# RS1xxxx register map
Vendor: Silicon Lab Inc.; Series: ARMCM4; File version: 1.2
CPU: CM4 r1p0, little endian, MPU, FPU, 6 interrupt priority bits
Registers are 32-bit, read-write, reset 0x0 unless marked. A register's access mark holds for its fields unless they carry their own. Offsets are from the block's base; [hi:lo] are bit positions.

## BAND_GAP_TOP
Base 0x2405A400
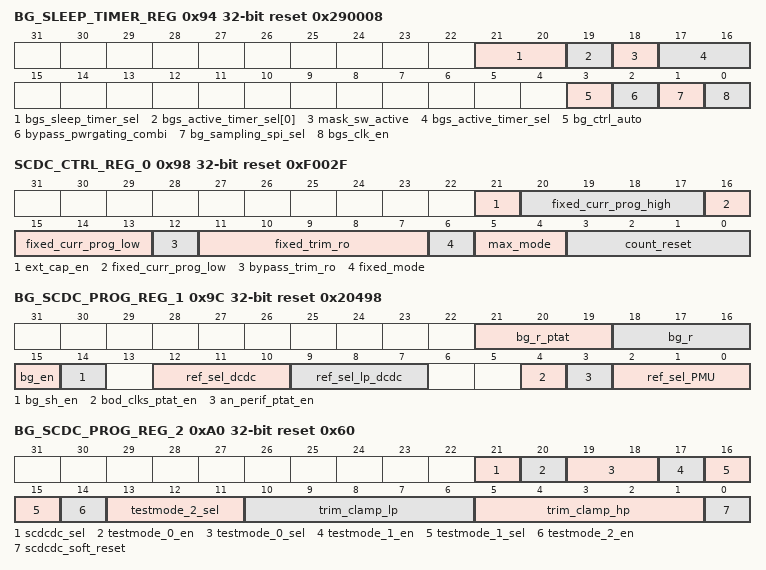
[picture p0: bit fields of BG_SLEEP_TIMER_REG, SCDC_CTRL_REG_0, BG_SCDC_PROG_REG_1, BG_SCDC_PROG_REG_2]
0x94 BG_SLEEP_TIMER_REG reset 0x290008 — BG sleep timer register
  [21:20] bgs_sleep_timer_sel — sleep timer count is 2'd0: active_timer_count * 2^6 2'd1: active timer_count * 2^7 2'd2: active_timer_count * 2^8 2'd3: active_timer_count * 2^9
  [19] bgs_active_timer_sel[0] ro — taking one bit of bgs_active_timer_sel[17:16]
  [18] mask_sw_active — 1: disable comp clock in between sleep duration
  [17:16] bgs_active_timer_sel — Active timer select
  [3] bg_ctrl_auto — bg_en , bg_sh_en automatically enables or take values though SPI
    1=Enable (bg_en and bg_sh_en are automatically controlled); 0=Disable (bg_en and sh_en take values from SPI.)
  [2] bypass_pwrgating_combi — Powergating is disabled for combi logic . It will always be ON.
  [1] bg_sampling_spi_sel — enable bandgap sampling through spi / pin
    1=Through_SPI (Bandgap sampling through spi); 0=Through_Pin (Band gap sampling through pin(sleep_en))
  [0] bgs_clk_en — bandgap sampling enable through spi
0x98 SCDC_CTRL_REG_0 reset 0xF002F — SCDC Control register
  [21] ext_cap_en — To change current trim bits to high or low through spi, based on high power or low power mode.When 0, curr prog value is 0.
  [20:17] fixed_curr_prog_high — Current prog value to take when ext cap en is high and sel_high freq_ext_b is 0
  [16:13] fixed_curr_prog_low — Current prog value to take when ext cap en is high and sel_high freq_ext_b is 1
  [12] bypass_trim_ro — To program the trim value manually, irrespective of the fsm
  [11:7] fixed_trim_ro — Manual trim word
  [6] fixed_mode
  [5:4] max_mode — maximum mode it can go to
  [3:0] count_reset — Count reset value, count threshold will be doubler this value
0x9C BG_SCDC_PROG_REG_1 reset 0x20498 — BG SCDC programme register
  [21:19] bg_r_ptat — Bandgap voltage programming
  [18:16] bg_r — Bandgap voltage programming
  [15] bg_en — bg_en from spi
  [14] bg_sh_en — bg_sh_en from spi
  [12:10] ref_sel_dcdc — DCDC output programming vref_1p1/vref_1p05
  [9:7] ref_sel_lp_dcdc — DCDC output programming in LDO high/low power mode
  [4] bod_clks_ptat_en — 1 - To enable ptat currents to clocks and bod(cmp_npss)
  [3] an_perif_ptat_en — 1 - To enable ptat currents to analog peripherals
  [2:0] ref_sel_PMU — 3'd0 - 1.2V, 3'd1 - 1.15V, 3'd2 - 1.1V, 3'd3 - 1.05V 3'd4 - 1.0V 3'd5 - 0.95V,3'd6 - 0.9V,3'd7 - 0.85V
0xA0 BG_SCDC_PROG_REG_2 reset 0x60 — BG SCDC programme register 2
  [21] scdcdc_sel — To switch to SCDCDC mode from LDO mode.1 - SCDC mode,0 - LDO mode
    1=SCDC_Mode; 0=LDO_Mode
  [20] testmode_0_en — Enable for output on to BG_TESTMODE0
  [19:18] testmode_0_sel — Test mode 0 select
  [17] testmode_1_en — To enable test mux for BG_TESTMODE1
  [16:15] testmode_1_sel — testmode 1 select
  [14] testmode_2_en — To enable testmux for BG_TESTMODE2
  [13:11] testmode_2_sel — test mode 2 select
  [10:6] trim_clamp_lp — trim value lower clamp value when sel high freq_b is 1
  [5:1] trim_clamp_hp — trim value lower clamp value when sel high freq_b is 0
  [0] scdcdc_soft_reset — soft reset signal for scdcdc fsm
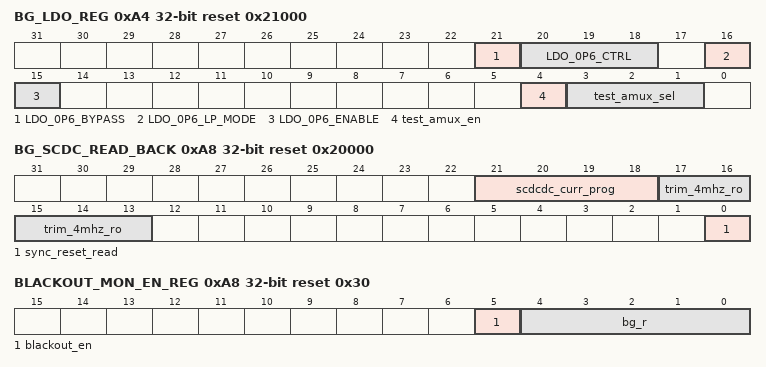
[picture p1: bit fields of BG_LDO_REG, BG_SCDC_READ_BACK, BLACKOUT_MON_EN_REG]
0xA4 BG_LDO_REG reset 0x21000 — BG LDO Register
  [21] LDO_0P6_BYPASS — bypass signal for DCDC1p1_lp_500uA
  [20:18] LDO_0P6_CTRL — vref for DCDC1p1_lp_500uA
  [16] LDO_0P6_LP_MODE — enable low power mode, otherwise in high power mode
  [15] LDO_0P6_ENABLE — enable digital LDO
  [4] test_amux_en — Enable analog mux to test reference voltages
  [3:1] test_amux_sel — Select for analog mux
0xA8 BG_SCDC_READ_BACK ro reset 0x20000
  [21:18] scdcdc_curr_prog — Scdcdc curr prog read back
  [17:13] trim_4mhz_ro — Trim value for scdcdc ring oscillator
  [0] sync_reset_read — Read back for sync reset with ro clock
0xA8 BLACKOUT_MON_EN_REG reset 0x30
  [5] blackout_en — Control signal for blackout monitor from SPI
  [4:0] bg_r — Bandgap Voltage Programming
